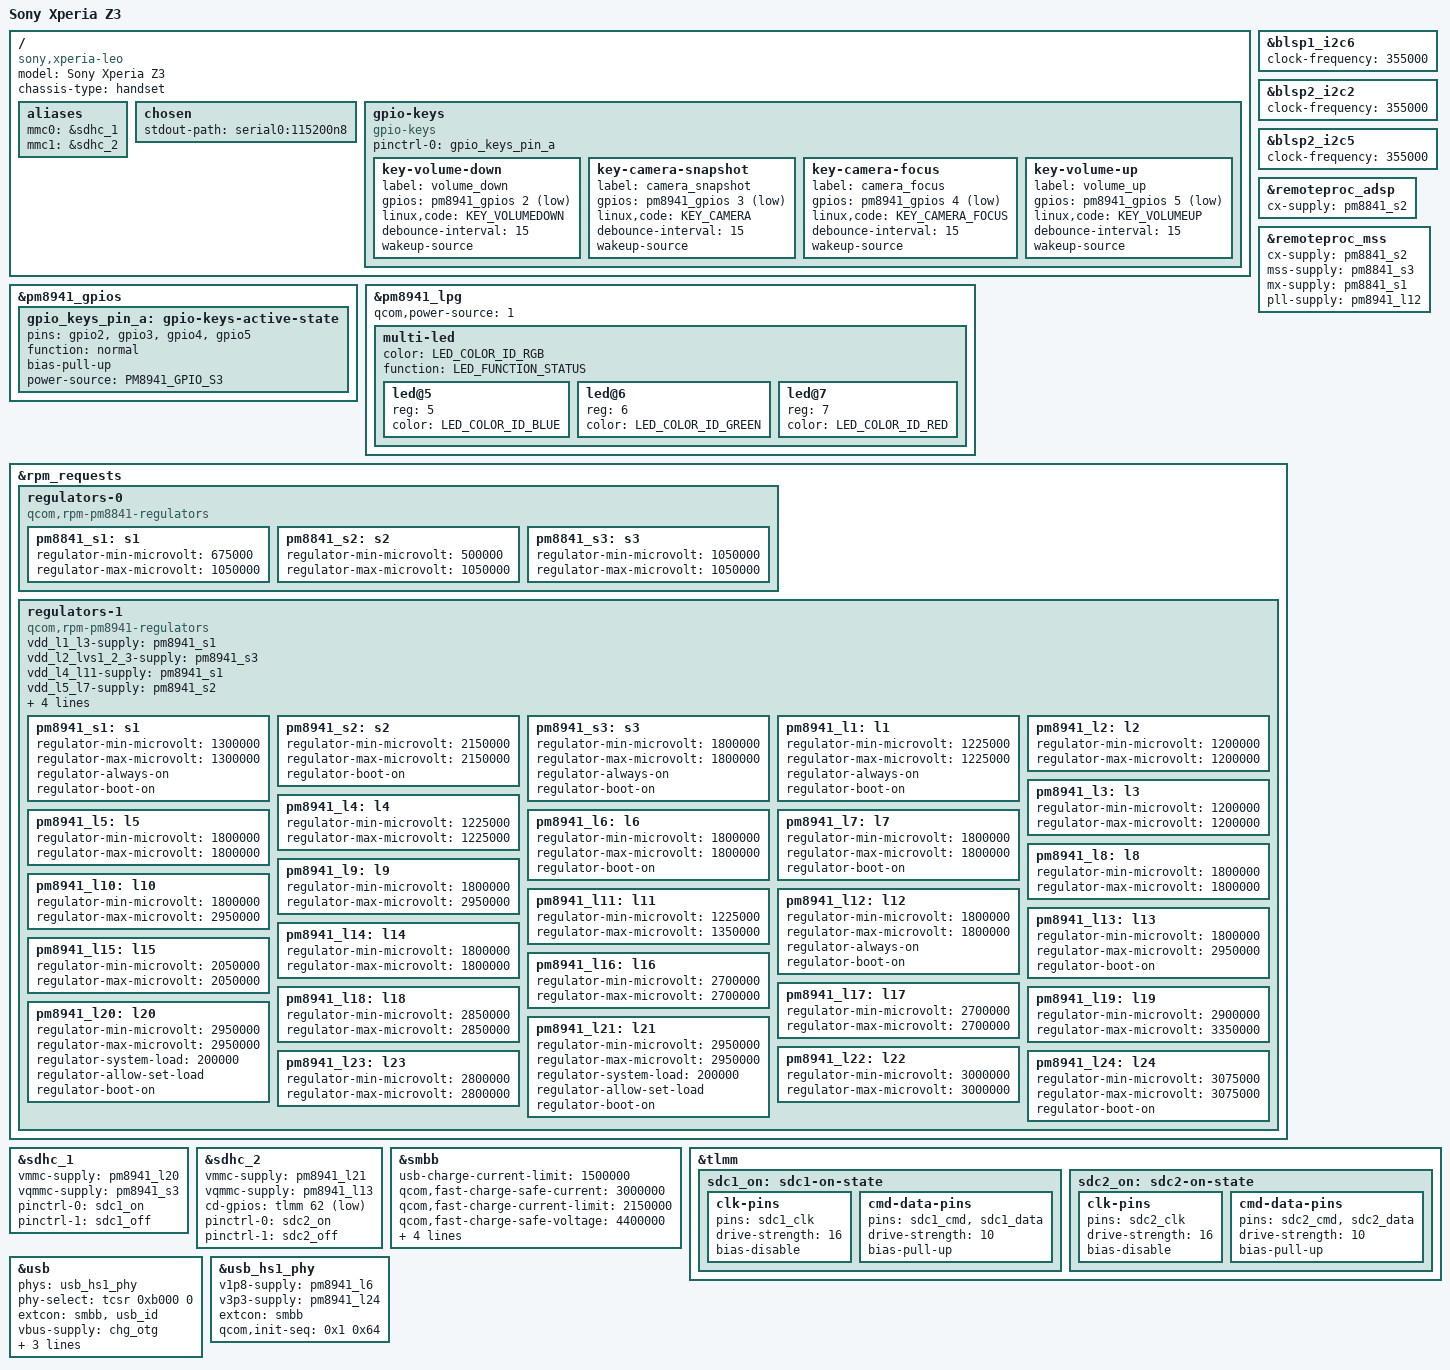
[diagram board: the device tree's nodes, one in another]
// SPDX-License-Identifier: GPL-2.0
#include "qcom-msm8974pro.dtsi"
#include "qcom-pm8841.dtsi"
#include "qcom-pm8941.dtsi"
#include <dt-bindings/input/input.h>
#include <dt-bindings/leds/common.h>
#include <dt-bindings/pinctrl/qcom,pmic-gpio.h>

/ {
	model = "Sony Xperia Z3";
	compatible = "sony,xperia-leo", "qcom,msm8974pro", "qcom,msm8974";
	chassis-type = "handset";

	aliases {
		mmc0 = &sdhc_1;
		mmc1 = &sdhc_2;
	};

	chosen {
		stdout-path = "serial0:115200n8";
	};

	gpio-keys {
		compatible = "gpio-keys";

		pinctrl-0 = <&gpio_keys_pin_a>;
		pinctrl-names = "default";

		key-volume-down {
			label = "volume_down";
			gpios = <&pm8941_gpios 2 GPIO_ACTIVE_LOW>;
			linux,code = <KEY_VOLUMEDOWN>;
			debounce-interval = <15>;
			wakeup-source;
		};

		key-camera-snapshot {
			label = "camera_snapshot";
			gpios = <&pm8941_gpios 3 GPIO_ACTIVE_LOW>;
			linux,code = <KEY_CAMERA>;
			debounce-interval = <15>;
			wakeup-source;
		};

		key-camera-focus {
			label = "camera_focus";
			gpios = <&pm8941_gpios 4 GPIO_ACTIVE_LOW>;
			linux,code = <KEY_CAMERA_FOCUS>;
			debounce-interval = <15>;
			wakeup-source;
		};

		key-volume-up {
			label = "volume_up";
			gpios = <&pm8941_gpios 5 GPIO_ACTIVE_LOW>;
			linux,code = <KEY_VOLUMEUP>;
			debounce-interval = <15>;
			wakeup-source;
		};
	};
};

&blsp1_i2c6 {
	clock-frequency = <355000>;

	status = "okay";

	/* NFC PN547 @ 0x28 */
};

&blsp2_i2c2 {
	clock-frequency = <355000>;

	status = "okay";

	/* Touchscreen synaptics @ 0x2c */
};

&blsp2_i2c5 {
	clock-frequency = <355000>;

	status = "okay";

	/* Amplifier top TFA98xx @ 0x34 */
	/* Amplifier bottom TFA98xx @ 0x35 */
	/* HDMI/MHL bridge SII8620 @ 0x72 or 0x39 */
};

&pm8941_gpios {
	gpio_keys_pin_a: gpio-keys-active-state {
		pins = "gpio2", "gpio3", "gpio4", "gpio5";
		function = "normal";
		bias-pull-up;
		power-source = <PM8941_GPIO_S3>;
	};
};

&pm8941_lpg {
	qcom,power-source = <1>;

	status = "okay";

	multi-led {
		color = <LED_COLOR_ID_RGB>;
		function = LED_FUNCTION_STATUS;

		#address-cells = <1>;
		#size-cells = <0>;

		led@5 {
			reg = <5>;
			color = <LED_COLOR_ID_BLUE>;
		};

		led@6 {
			reg = <6>;
			color = <LED_COLOR_ID_GREEN>;
		};

		led@7 {
			reg = <7>;
			color = <LED_COLOR_ID_RED>;
		};
	};
};

&remoteproc_adsp {
	cx-supply = <&pm8841_s2>;

	status = "okay";
};

&remoteproc_mss {
	cx-supply = <&pm8841_s2>;
	mss-supply = <&pm8841_s3>;
	mx-supply = <&pm8841_s1>;
	pll-supply = <&pm8941_l12>;

	status = "okay";
};

&rpm_requests {
	regulators-0 {
		compatible = "qcom,rpm-pm8841-regulators";

		pm8841_s1: s1 {
			regulator-min-microvolt = <675000>;
			regulator-max-microvolt = <1050000>;
		};

		pm8841_s2: s2 {
			regulator-min-microvolt = <500000>;
			regulator-max-microvolt = <1050000>;
		};

		pm8841_s3: s3 {
			regulator-min-microvolt = <1050000>;
			regulator-max-microvolt = <1050000>;
		};

		// s4? 815000 - 900000
	};

	regulators-1 {
		compatible = "qcom,rpm-pm8941-regulators";

		vdd_l1_l3-supply = <&pm8941_s1>;
		vdd_l2_lvs1_2_3-supply = <&pm8941_s3>;
		vdd_l4_l11-supply = <&pm8941_s1>;
		vdd_l5_l7-supply = <&pm8941_s2>;
		vdd_l6_l12_l14_l15-supply = <&pm8941_s2>;
		vdd_l9_l10_l17_l22-supply = <&vreg_boost>;
		vdd_l13_l20_l23_l24-supply = <&vreg_boost>;
		vdd_l21-supply = <&vreg_boost>;

		pm8941_s1: s1 {
			regulator-min-microvolt = <1300000>;
			regulator-max-microvolt = <1300000>;
			regulator-always-on;
			regulator-boot-on;
		};

		pm8941_s2: s2 {
			regulator-min-microvolt = <2150000>;
			regulator-max-microvolt = <2150000>;
			regulator-boot-on;
		};

		pm8941_s3: s3 {
			regulator-min-microvolt = <1800000>;
			regulator-max-microvolt = <1800000>;
			regulator-always-on;
			regulator-boot-on;
		};

		pm8941_l1: l1 {
			regulator-min-microvolt = <1225000>;
			regulator-max-microvolt = <1225000>;
			regulator-always-on;
			regulator-boot-on;
		};

		pm8941_l2: l2 {
			regulator-min-microvolt = <1200000>;
			regulator-max-microvolt = <1200000>;
		};

		pm8941_l3: l3 {
			regulator-min-microvolt = <1200000>;
			regulator-max-microvolt = <1200000>;
		};

		pm8941_l4: l4 {
			regulator-min-microvolt = <1225000>;
			regulator-max-microvolt = <1225000>;
		};

		pm8941_l5: l5 {
			regulator-min-microvolt = <1800000>;
			regulator-max-microvolt = <1800000>;
		};

		pm8941_l6: l6 {
			regulator-min-microvolt = <1800000>;
			regulator-max-microvolt = <1800000>;
			regulator-boot-on;
		};

		pm8941_l7: l7 {
			regulator-min-microvolt = <1800000>;
			regulator-max-microvolt = <1800000>;
			regulator-boot-on;
		};

		pm8941_l8: l8 {
			regulator-min-microvolt = <1800000>;
			regulator-max-microvolt = <1800000>;
		};

		pm8941_l9: l9 {
			regulator-min-microvolt = <1800000>;
			regulator-max-microvolt = <2950000>;
		};

		pm8941_l10: l10 {
			regulator-min-microvolt = <1800000>;
			regulator-max-microvolt = <2950000>;
		};

		pm8941_l11: l11 {
			regulator-min-microvolt = <1225000>;
			regulator-max-microvolt = <1350000>;
		};

		pm8941_l12: l12 {
			regulator-min-microvolt = <1800000>;
			regulator-max-microvolt = <1800000>;
			regulator-always-on;
			regulator-boot-on;
		};

		pm8941_l13: l13 {
			regulator-min-microvolt = <1800000>;
			regulator-max-microvolt = <2950000>;
			regulator-boot-on;
		};

		pm8941_l14: l14 {
			regulator-min-microvolt = <1800000>;
			regulator-max-microvolt = <1800000>;
		};

		pm8941_l15: l15 {
			regulator-min-microvolt = <2050000>;
			regulator-max-microvolt = <2050000>;
		};

		pm8941_l16: l16 {
			regulator-min-microvolt = <2700000>;
			regulator-max-microvolt = <2700000>;
		};

		pm8941_l17: l17 {
			regulator-min-microvolt = <2700000>;
			regulator-max-microvolt = <2700000>;
		};

		pm8941_l18: l18 {
			regulator-min-microvolt = <2850000>;
			regulator-max-microvolt = <2850000>;
		};

		pm8941_l19: l19 {
			regulator-min-microvolt = <2900000>;
			regulator-max-microvolt = <3350000>;
		};

		pm8941_l20: l20 {
			regulator-min-microvolt = <2950000>;
			regulator-max-microvolt = <2950000>;
			regulator-system-load = <200000>;
			regulator-allow-set-load;
			regulator-boot-on;
		};

		pm8941_l21: l21 {
			regulator-min-microvolt = <2950000>;
			regulator-max-microvolt = <2950000>;
			regulator-system-load = <200000>;
			regulator-allow-set-load;
			regulator-boot-on;
		};

		pm8941_l22: l22 {
			regulator-min-microvolt = <3000000>;
			regulator-max-microvolt = <3000000>;
		};

		pm8941_l23: l23 {
			regulator-min-microvolt = <2800000>;
			regulator-max-microvolt = <2800000>;
		};

		pm8941_l24: l24 {
			regulator-min-microvolt = <3075000>;
			regulator-max-microvolt = <3075000>;
			regulator-boot-on;
		};
	};
};

&sdhc_1 {
	vmmc-supply = <&pm8941_l20>;
	vqmmc-supply = <&pm8941_s3>;

	pinctrl-0 = <&sdc1_on>;
	pinctrl-1 = <&sdc1_off>;
	pinctrl-names = "default", "sleep";

	status = "okay";
};

&sdhc_2 {
	vmmc-supply = <&pm8941_l21>;
	vqmmc-supply = <&pm8941_l13>;

	cd-gpios = <&tlmm 62 GPIO_ACTIVE_LOW>;

	pinctrl-0 = <&sdc2_on>;
	pinctrl-1 = <&sdc2_off>;
	pinctrl-names = "default", "sleep";

	status = "okay";
};

&smbb {
	usb-charge-current-limit = <1500000>;
	qcom,fast-charge-safe-current = <3000000>;
	qcom,fast-charge-current-limit = <2150000>;
	qcom,fast-charge-safe-voltage = <4400000>;
	qcom,fast-charge-high-threshold-voltage = <4350000>;
	qcom,auto-recharge-threshold-voltage = <4280000>;
	qcom,minimum-input-voltage = <4200000>;
};

&tlmm {
	sdc1_on: sdc1-on-state {
		clk-pins {
			pins = "sdc1_clk";
			drive-strength = <16>;
			bias-disable;
		};

		cmd-data-pins {
			pins = "sdc1_cmd", "sdc1_data";
			drive-strength = <10>;
			bias-pull-up;
		};
	};

	sdc2_on: sdc2-on-state {
		clk-pins {
			pins = "sdc2_clk";
			drive-strength = <16>;
			bias-disable;
		};

		cmd-data-pins {
			pins = "sdc2_cmd", "sdc2_data";
			drive-strength = <10>;
			bias-pull-up;
		};
	};
};

&usb {
	phys = <&usb_hs1_phy>;
	phy-select = <&tcsr 0xb000 0>;
	extcon = <&smbb>, <&usb_id>;
	vbus-supply = <&chg_otg>;

	hnp-disable;
	srp-disable;
	adp-disable;

	status = "okay";
};

&usb_hs1_phy {
	v1p8-supply = <&pm8941_l6>;
	v3p3-supply = <&pm8941_l24>;

	extcon = <&smbb>;
	qcom,init-seq = /bits/ 8 <0x1 0x64>;

	status = "okay";
};
